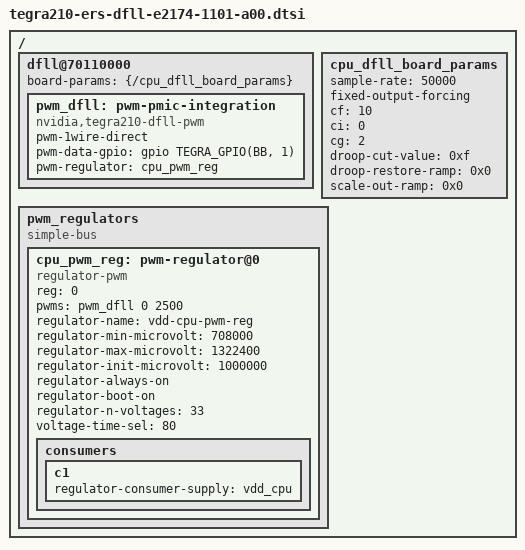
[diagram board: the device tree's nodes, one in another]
#include <dt-bindings/gpio/tegra-gpio.h>

/ {
	dfll@70110000 {
		board-params = <&{/cpu_dfll_board_params}>;
		status = "okay";
		pwm_dfll: pwm-pmic-integration {
			compatible = "nvidia,tegra210-dfll-pwm";
			pwm-1wire-direct;
			pwm-data-gpio = <&gpio TEGRA_GPIO(BB, 1) 0>;
			#pwm-cells = <2>;
			pwm-regulator = <&cpu_pwm_reg>;
		};
	};

	cpu_dfll_board_params {
		sample-rate = <50000>;
		fixed-output-forcing;
		cf = <10>;
		ci = <0>;
		cg = <2>;
		droop-cut-value = <0xf>;
		droop-restore-ramp = <0x0>;
		scale-out-ramp = <0x0>;
	};

	pwm_regulators {
		compatible = "simple-bus";
		#address-cells = <1>;
		#size-cells = <0>;

		cpu_pwm_reg: pwm-regulator@0 {
			reg = <0>;
			compatible = "regulator-pwm";
			pwms = <&pwm_dfll 0 2500>;
			regulator-name = "vdd-cpu-pwm-reg";
			regulator-min-microvolt = <708000>;
			regulator-max-microvolt = <1322400>;
			regulator-init-microvolt = <1000000>;
			regulator-always-on;
			regulator-boot-on;
			regulator-n-voltages = <33>;
			voltage-time-sel = <80>;
			consumers {
				c1 {
					regulator-consumer-supply = "vdd_cpu";
				};
			};
		};
	};
};
